AUTOSAR XML (schema 00046)
package /ComponentTypes
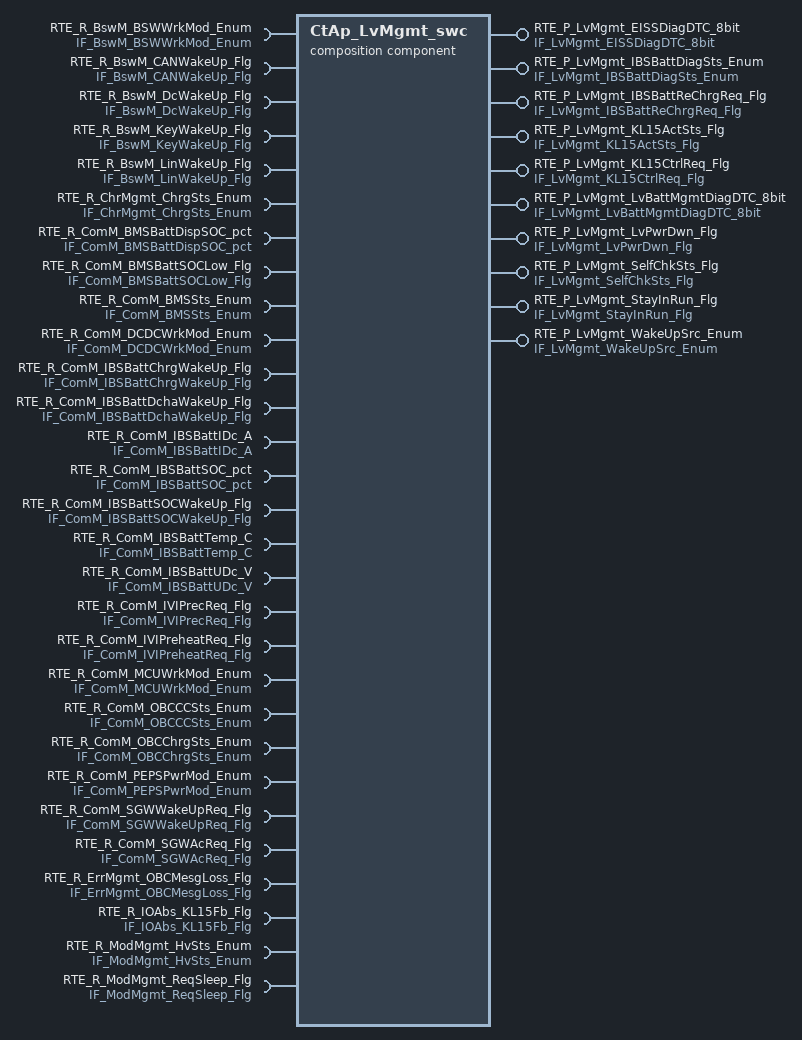
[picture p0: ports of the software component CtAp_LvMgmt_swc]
  composition sw component type CtAp_LvMgmt_swc
    29 x require port:
      RTE_R_BswM_BSWWrkMod_Enum: nonqueued-receiver-com-spec{data-element=tec_BswM_BSWWrkMod_Enum, filter=data-filter-type=ALWAYS, init-value=0}, required-interface=IF_BswM_BSWWrkMod_Enum
      RTE_R_BswM_CANWakeUp_Flg: nonqueued-receiver-com-spec{data-element=tec_BswM_CANWakeUp_Flg, filter=data-filter-type=ALWAYS, init-value=0}, required-interface=IF_BswM_CANWakeUp_Flg
      RTE_R_BswM_DcWakeUp_Flg: nonqueued-receiver-com-spec{data-element=tec_BswM_DcWakeUp_Flg, filter=data-filter-type=ALWAYS, init-value=0}, required-interface=IF_BswM_DcWakeUp_Flg
      RTE_R_BswM_KeyWakeUp_Flg: nonqueued-receiver-com-spec{data-element=tec_BswM_KeyWakeUp_Flg, filter=data-filter-type=ALWAYS, init-value=0}, required-interface=IF_BswM_KeyWakeUp_Flg
      RTE_R_BswM_LinWakeUp_Flg: nonqueued-receiver-com-spec{data-element=tec_BswM_LinWakeUp_Flg, filter=data-filter-type=ALWAYS, init-value=0}, required-interface=IF_BswM_LinWakeUp_Flg
      RTE_R_ChrMgmt_ChrgSts_Enum: nonqueued-receiver-com-spec{data-element=tec_ChrMgmt_ChrgSts_Enum, filter=data-filter-type=ALWAYS, init-value=0}, required-interface=IF_ChrMgmt_ChrgSts_Enum
      RTE_R_ComM_BMSBattDispSOC_pct: nonqueued-receiver-com-spec{data-element=tec_ComM_BMSBattDispSOC_pct, filter=data-filter-type=ALWAYS, init-value=0}, required-interface=IF_ComM_BMSBattDispSOC_pct
      RTE_R_ComM_BMSBattSOCLow_Flg: nonqueued-receiver-com-spec{data-element=tec_ComM_BMSBattSOCLow_Flg, filter=data-filter-type=ALWAYS, init-value=0}, required-interface=IF_ComM_BMSBattSOCLow_Flg
      RTE_R_ComM_BMSSts_Enum: nonqueued-receiver-com-spec{data-element=tec_ComM_BMSSts_Enum, filter=data-filter-type=ALWAYS, init-value=0}, required-interface=IF_ComM_BMSSts_Enum
      RTE_R_ComM_DCDCWrkMod_Enum: nonqueued-receiver-com-spec{data-element=tec_ComM_DCDCWrkMod_Enum, filter=data-filter-type=ALWAYS, init-value=0}, required-interface=IF_ComM_DCDCWrkMod_Enum
      RTE_R_ComM_IBSBattChrgWakeUp_Flg: nonqueued-receiver-com-spec{data-element=tec_ComM_IBSBattChrgWakeUp_Flg, filter=data-filter-type=ALWAYS, init-value=0}, required-interface=IF_ComM_IBSBattChrgWakeUp_Flg
      RTE_R_ComM_IBSBattDchaWakeUp_Flg: nonqueued-receiver-com-spec{data-element=tec_ComM_IBSBattDchaWakeUp_Flg, filter=data-filter-type=ALWAYS, init-value=0}, required-interface=IF_ComM_IBSBattDchaWakeUp_Flg
      RTE_R_ComM_IBSBattIDc_A: nonqueued-receiver-com-spec{data-element=tec_ComM_IBSBattIDc_A, filter=data-filter-type=ALWAYS, init-value=0}, required-interface=IF_ComM_IBSBattIDc_A
      RTE_R_ComM_IBSBattSOC_pct: nonqueued-receiver-com-spec{data-element=tec_ComM_IBSBattSOC_pct, filter=data-filter-type=ALWAYS, init-value=0}, required-interface=IF_ComM_IBSBattSOC_pct
      RTE_R_ComM_IBSBattSOCWakeUp_Flg: nonqueued-receiver-com-spec{data-element=tec_ComM_IBSBattSOCWakeUp_Flg, filter=data-filter-type=ALWAYS, init-value=0}, required-interface=IF_ComM_IBSBattSOCWakeUp_Flg
      RTE_R_ComM_IBSBattTemp_C: nonqueued-receiver-com-spec{data-element=tec_ComM_IBSBattTemp_C, filter=data-filter-type=ALWAYS, init-value=0}, required-interface=IF_ComM_IBSBattTemp_C
      RTE_R_ComM_IBSBattUDc_V: nonqueued-receiver-com-spec{data-element=tec_ComM_IBSBattUDc_V, filter=data-filter-type=ALWAYS, init-value=0}, required-interface=IF_ComM_IBSBattUDc_V
      RTE_R_ComM_IVIPrecReq_Flg: nonqueued-receiver-com-spec{data-element=tec_ComM_IVIPrecReq_Flg, filter=data-filter-type=ALWAYS, init-value=0}, required-interface=IF_ComM_IVIPrecReq_Flg
      RTE_R_ComM_IVIPreheatReq_Flg: nonqueued-receiver-com-spec{data-element=tec_ComM_IVIPreheatReq_Flg, filter=data-filter-type=ALWAYS, init-value=0}, required-interface=IF_ComM_IVIPreheatReq_Flg
      RTE_R_ComM_MCUWrkMod_Enum: nonqueued-receiver-com-spec{data-element=tec_ComM_MCUWrkMod_Enum, filter=data-filter-type=ALWAYS, init-value=0}, required-interface=IF_ComM_MCUWrkMod_Enum
      RTE_R_ComM_OBCCCSts_Enum: nonqueued-receiver-com-spec{data-element=tec_ComM_OBCCCSts_Enum, filter=data-filter-type=ALWAYS, init-value=0}, required-interface=IF_ComM_OBCCCSts_Enum
      RTE_R_ComM_OBCChrgSts_Enum: nonqueued-receiver-com-spec{data-element=tec_ComM_OBCChrgSts_Enum, filter=data-filter-type=ALWAYS, init-value=0}, required-interface=IF_ComM_OBCChrgSts_Enum
      RTE_R_ComM_PEPSPwrMod_Enum: nonqueued-receiver-com-spec{data-element=tec_ComM_PEPSPwrMod_Enum, filter=data-filter-type=ALWAYS, init-value=0}, required-interface=IF_ComM_PEPSPwrMod_Enum
      RTE_R_ComM_SGWWakeUpReq_Flg: nonqueued-receiver-com-spec{data-element=tec_ComM_SGWWakeUpReq_Flg, filter=data-filter-type=ALWAYS, init-value=0}, required-interface=IF_ComM_SGWWakeUpReq_Flg
      RTE_R_ComM_SGWAcReq_Flg: nonqueued-receiver-com-spec{data-element=tec_ComM_SGWAcReq_Flg, filter=data-filter-type=ALWAYS, init-value=0}, required-interface=IF_ComM_SGWAcReq_Flg
      RTE_R_ErrMgmt_OBCMesgLoss_Flg: nonqueued-receiver-com-spec{data-element=tec_ErrMgmt_OBCMesgLoss_Flg, filter=data-filter-type=ALWAYS, init-value=0}, required-interface=IF_ErrMgmt_OBCMesgLoss_Flg
      RTE_R_IOAbs_KL15Fb_Flg: nonqueued-receiver-com-spec{data-element=tec_IOAbs_KL15Fb_Flg, filter=data-filter-type=ALWAYS, init-value=0}, required-interface=IF_IOAbs_KL15Fb_Flg
      RTE_R_ModMgmt_HvSts_Enum: nonqueued-receiver-com-spec{data-element=tec_ModMgmt_HvSts_Enum, filter=data-filter-type=ALWAYS, init-value=0}, required-interface=IF_ModMgmt_HvSts_Enum
      RTE_R_ModMgmt_ReqSleep_Flg: nonqueued-receiver-com-spec{data-element=tec_ModMgmt_ReqSleep_Flg, filter=data-filter-type=ALWAYS, init-value=0}, required-interface=IF_ModMgmt_ReqSleep_Flg
    10 x provide port:
      RTE_P_LvMgmt_EISSDiagDTC_8bit: nonqueued-sender-com-spec{data-element=tec_LvMgmt_EISSDiagDTC_8bit, init-value=0}, provided-interface=IF_LvMgmt_EISSDiagDTC_8bit
      RTE_P_LvMgmt_IBSBattDiagSts_Enum: nonqueued-sender-com-spec{data-element=tec_LvMgmt_IBSBattDiagSts_Enum, init-value=0}, provided-interface=IF_LvMgmt_IBSBattDiagSts_Enum
      RTE_P_LvMgmt_IBSBattReChrgReq_Flg: nonqueued-sender-com-spec{data-element=tec_LvMgmt_IBSBattReChrgReq_Flg, init-value=0}, provided-interface=IF_LvMgmt_IBSBattReChrgReq_Flg
      RTE_P_LvMgmt_KL15ActSts_Flg: nonqueued-sender-com-spec{data-element=tec_LvMgmt_KL15ActSts_Flg, init-value=0}, provided-interface=IF_LvMgmt_KL15ActSts_Flg
      RTE_P_LvMgmt_KL15CtrlReq_Flg: nonqueued-sender-com-spec{data-element=tec_LvMgmt_KL15CtrlReq_Flg, init-value=0}, provided-interface=IF_LvMgmt_KL15CtrlReq_Flg
      RTE_P_LvMgmt_LvBattMgmtDiagDTC_8bit: nonqueued-sender-com-spec{data-element=tec_LvMgmt_LvBattMgmtDiagDTC_8bit, init-value=0}, provided-interface=IF_LvMgmt_LvBattMgmtDiagDTC_8bit
      RTE_P_LvMgmt_LvPwrDwn_Flg: nonqueued-sender-com-spec{data-element=tec_LvMgmt_LvPwrDwn_Flg, init-value=0}, provided-interface=IF_LvMgmt_LvPwrDwn_Flg
      RTE_P_LvMgmt_SelfChkSts_Flg: nonqueued-sender-com-spec{data-element=tec_LvMgmt_SelfChkSts_Flg, init-value=0}, provided-interface=IF_LvMgmt_SelfChkSts_Flg
      RTE_P_LvMgmt_StayInRun_Flg: nonqueued-sender-com-spec{data-element=tec_LvMgmt_StayInRun_Flg, init-value=0}, provided-interface=IF_LvMgmt_StayInRun_Flg
      RTE_P_LvMgmt_WakeUpSrc_Enum: nonqueued-sender-com-spec{data-element=tec_LvMgmt_WakeUpSrc_Enum, init-value=0}, provided-interface=IF_LvMgmt_WakeUpSrc_Enum
    component CtAp_WakeUpRsn: type=CtAp_WakeUpRsn
    component CtAp_ElSSDiag: type=CtAp_ElSSDiag
    component CtAp_LvBattMgmt: type=CtAp_LvBattMgmt
    delegate CtAp_ElSSDiag.RTE_R_BswM_BSWWrkMod_Enum <-> outer port RTE_R_BswM_BSWWrkMod_Enum
    delegate CtAp_ElSSDiag.RTE_R_BswM_CANWakeUp_Flg <-> outer port RTE_R_BswM_CANWakeUp_Flg
    delegate CtAp_ElSSDiag.RTE_R_BswM_KeyWakeUp_Flg <-> outer port RTE_R_BswM_KeyWakeUp_Flg
    delegate CtAp_ElSSDiag.RTE_R_BswM_LinWakeUp_Flg <-> outer port RTE_R_BswM_LinWakeUp_Flg
    delegate CtAp_ElSSDiag.RTE_R_ChrMgmt_ChrgSts_Enum <-> outer port RTE_R_ChrMgmt_ChrgSts_Enum
    delegate CtAp_ElSSDiag.RTE_R_ComM_BMSSts_Enum <-> outer port RTE_R_ComM_BMSSts_Enum
    delegate CtAp_ElSSDiag.RTE_R_ComM_DCDCWrkMod_Enum <-> outer port RTE_R_ComM_DCDCWrkMod_Enum
    delegate CtAp_ElSSDiag.RTE_R_ComM_IBSBattSOC_pct <-> outer port RTE_R_ComM_IBSBattSOC_pct
    delegate CtAp_ElSSDiag.RTE_R_ComM_MCUWrkMod_Enum <-> outer port RTE_R_ComM_MCUWrkMod_Enum
    delegate CtAp_ElSSDiag.RTE_R_ComM_OBCChrgSts_Enum <-> outer port RTE_R_ComM_OBCChrgSts_Enum
    delegate CtAp_ElSSDiag.RTE_R_ErrMgmt_OBCMesgLoss_Flg <-> outer port RTE_R_ErrMgmt_OBCMesgLoss_Flg
    delegate CtAp_ElSSDiag.RTE_R_IOAbs_KL15Fb_Flg <-> outer port RTE_R_IOAbs_KL15Fb_Flg
    connect CtAp_WakeUpRsn.RTE_P_LvMgmt_WakeUpReq_Flg -> CtAp_ElSSDiag.RTE_R_LvMgmt_WakeUpReq_Flg
    delegate CtAp_ElSSDiag.RTE_R_ModMgmt_HvSts_Enum <-> outer port RTE_R_ModMgmt_HvSts_Enum
    delegate CtAp_ElSSDiag.RTE_R_ModMgmt_ReqSleep_Flg <-> outer port RTE_R_ModMgmt_ReqSleep_Flg
    delegate CtAp_LvBattMgmt.RTE_R_BswM_LinWakeUp_Flg <-> outer port RTE_R_BswM_LinWakeUp_Flg
    delegate CtAp_LvBattMgmt.RTE_R_ComM_BMSBattDispSOC_pct <-> outer port RTE_R_ComM_BMSBattDispSOC_pct
    delegate CtAp_LvBattMgmt.RTE_R_ComM_IBSBattChrgWakeUp_Flg <-> outer port RTE_R_ComM_IBSBattChrgWakeUp_Flg
    delegate CtAp_LvBattMgmt.RTE_R_ComM_IBSBattDchaWakeUp_Flg <-> outer port RTE_R_ComM_IBSBattDchaWakeUp_Flg
    delegate CtAp_LvBattMgmt.RTE_R_ComM_IBSBattIDc_A <-> outer port RTE_R_ComM_IBSBattIDc_A
    delegate CtAp_LvBattMgmt.RTE_R_ComM_IBSBattSOC_pct <-> outer port RTE_R_ComM_IBSBattSOC_pct
    delegate CtAp_LvBattMgmt.RTE_R_ComM_IBSBattSOCWakeUp_Flg <-> outer port RTE_R_ComM_IBSBattSOCWakeUp_Flg
    delegate CtAp_LvBattMgmt.RTE_R_ComM_IBSBattTemp_C <-> outer port RTE_R_ComM_IBSBattTemp_C
    delegate CtAp_LvBattMgmt.RTE_R_ComM_IBSBattUDc_V <-> outer port RTE_R_ComM_IBSBattUDc_V
    delegate CtAp_WakeUpRsn.RTE_R_BswM_CANWakeUp_Flg <-> outer port RTE_R_BswM_CANWakeUp_Flg
    delegate CtAp_WakeUpRsn.RTE_R_BswM_DcWakeUp_Flg <-> outer port RTE_R_BswM_DcWakeUp_Flg
    delegate CtAp_WakeUpRsn.RTE_R_BswM_KeyWakeUp_Flg <-> outer port RTE_R_BswM_KeyWakeUp_Flg
    delegate CtAp_WakeUpRsn.RTE_R_BswM_LinWakeUp_Flg <-> outer port RTE_R_BswM_LinWakeUp_Flg
    delegate CtAp_WakeUpRsn.RTE_R_ComM_BMSBattSOCLow_Flg <-> outer port RTE_R_ComM_BMSBattSOCLow_Flg
    delegate CtAp_WakeUpRsn.RTE_R_ComM_IBSBattSOC_pct <-> outer port RTE_R_ComM_IBSBattSOC_pct
    delegate CtAp_WakeUpRsn.RTE_R_ComM_IVIPrecReq_Flg <-> outer port RTE_R_ComM_IVIPrecReq_Flg
    delegate CtAp_WakeUpRsn.RTE_R_ComM_IVIPreheatReq_Flg <-> outer port RTE_R_ComM_IVIPreheatReq_Flg
    delegate CtAp_WakeUpRsn.RTE_R_ComM_OBCCCSts_Enum <-> outer port RTE_R_ComM_OBCCCSts_Enum
    delegate CtAp_WakeUpRsn.RTE_R_ComM_PEPSPwrMod_Enum <-> outer port RTE_R_ComM_PEPSPwrMod_Enum
    delegate CtAp_WakeUpRsn.RTE_R_ComM_SGWAcReq_Flg <-> outer port RTE_R_ComM_SGWAcReq_Flg
    delegate CtAp_WakeUpRsn.RTE_R_ComM_SGWWakeUpReq_Flg <-> outer port RTE_R_ComM_SGWWakeUpReq_Flg
    delegate CtAp_ElSSDiag.RTE_P_LvMgmt_EISSDiagDTC_8bit <-> outer port RTE_P_LvMgmt_EISSDiagDTC_8bit
    delegate CtAp_ElSSDiag.RTE_P_LvMgmt_KL15ActSts_Flg <-> outer port RTE_P_LvMgmt_KL15ActSts_Flg
    delegate CtAp_ElSSDiag.RTE_P_LvMgmt_KL15CtrlReq_Flg <-> outer port RTE_P_LvMgmt_KL15CtrlReq_Flg
    delegate CtAp_ElSSDiag.RTE_P_LvMgmt_LvPwrDwn_Flg <-> outer port RTE_P_LvMgmt_LvPwrDwn_Flg
    delegate CtAp_ElSSDiag.RTE_P_LvMgmt_SelfChkSts_Flg <-> outer port RTE_P_LvMgmt_SelfChkSts_Flg
    delegate CtAp_ElSSDiag.RTE_P_LvMgmt_StayInRun_Flg <-> outer port RTE_P_LvMgmt_StayInRun_Flg
    delegate CtAp_LvBattMgmt.RTE_P_LvMgmt_IBSBattDiagSts_Enum <-> outer port RTE_P_LvMgmt_IBSBattDiagSts_Enum
    delegate CtAp_LvBattMgmt.RTE_P_LvMgmt_IBSBattReChrgReq_Flg <-> outer port RTE_P_LvMgmt_IBSBattReChrgReq_Flg
    delegate CtAp_LvBattMgmt.RTE_P_LvMgmt_LvBattMgmtDiagDTC_8bit <-> outer port RTE_P_LvMgmt_LvBattMgmtDiagDTC_8bit
    delegate CtAp_WakeUpRsn.RTE_P_LvMgmt_WakeUpSrc_Enum <-> outer port RTE_P_LvMgmt_WakeUpSrc_Enum
